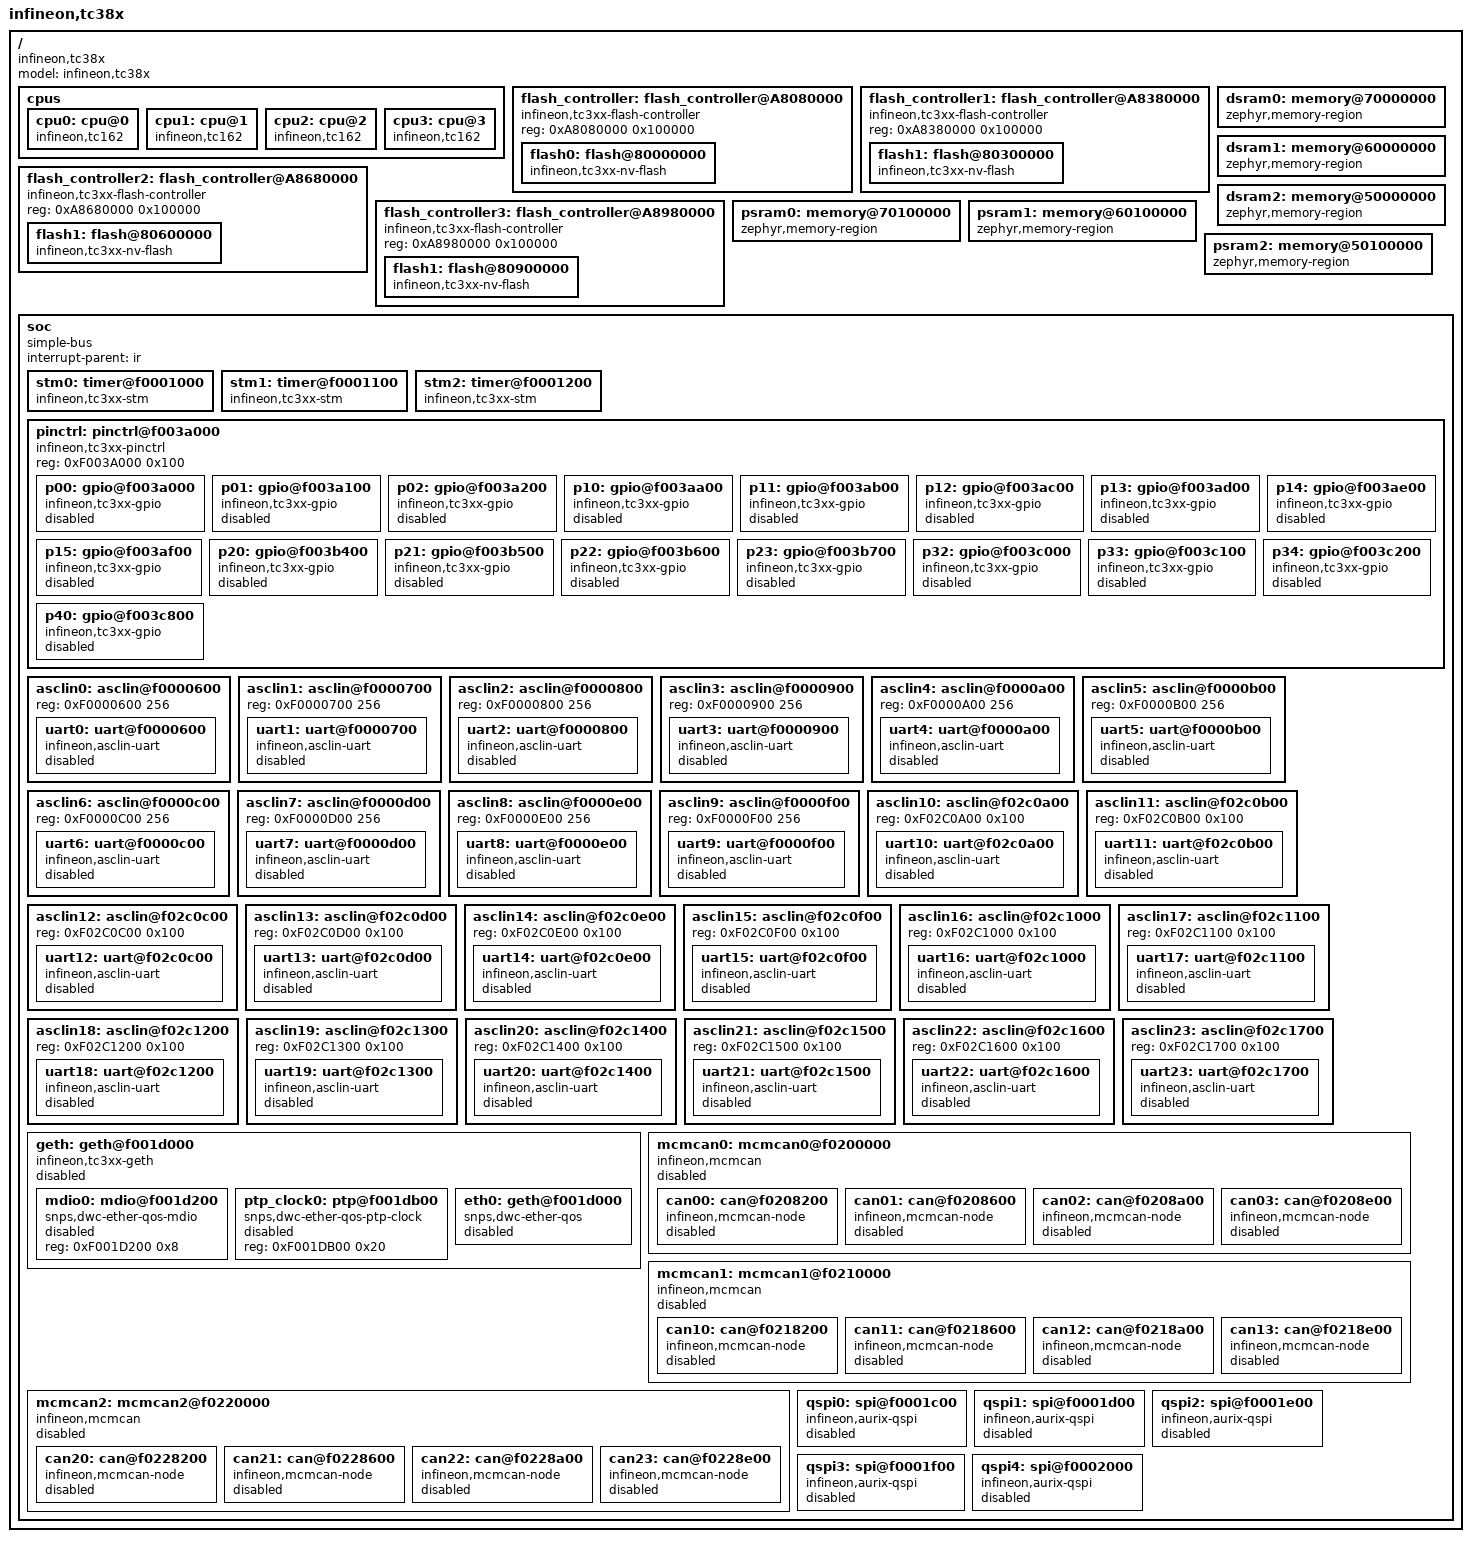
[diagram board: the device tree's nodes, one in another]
/*
 * Copyright (c) 2024 Infineon Technologies AG
 *
 * SPDX-License-Identifier: Apache-2.0
 */

#include <mem.h>
#include <freq.h>
#include <skeleton.dtsi>
#include <zephyr/dt-bindings/clock/tc3xx_clock.h>
#include <zephyr/dt-bindings/gpio/gpio.h>
#include <infineon/tc3xx/tc3xx-common.dtsi>
#include <infineon/tc3xx/tc38x-irq.h>

/ {
	model = "infineon,tc38x";
	compatible = "infineon,tc38x";

	cpus {
		#address-cells = <1>;
		#size-cells = <0>;

		cpu0: cpu@0 {
			compatible = "infineon,tc162";
			reg = <0>;
			clocks = <&fcpu0>;
		};
		cpu1: cpu@1 {
			compatible = "infineon,tc162";
			reg = <1>;
			clocks = <&fcpu1>;
		};
		cpu2: cpu@2 {
			compatible = "infineon,tc162";
			reg = <2>;
			clocks = <&fcpu2>;
		};
		cpu3: cpu@3 {
			compatible = "infineon,tc162";
			reg = <3>;
			clocks = <&fcpu3>;
		};
	};

	flash_controller: flash_controller@A8080000 {
		compatible = "infineon,tc3xx-flash-controller";
		#address-cells = <1>;
		#size-cells = <1>;
		reg = <0xA8080000 0x100000>;
		flash0: flash@80000000 {
			compatible = "infineon,tc3xx-nv-flash","soc-nv-flash";
			write-block-size = <256>;
			reg = <0x80000000 DT_SIZE_M(2)>;
		};
	};
	flash_controller1: flash_controller@A8380000 {
		compatible = "infineon,tc3xx-flash-controller";
		reg = <0xA8380000 0x100000>;
		#address-cells = <1>;
		#size-cells = <1>;
		flash1: flash@80300000 {
			compatible = "infineon,tc3xx-nv-flash","soc-nv-flash";
			write-block-size = <256>;
			reg = <0x80300000 DT_SIZE_M(2)>;
		};
	};
	flash_controller2: flash_controller@A8680000 {
		compatible = "infineon,tc3xx-flash-controller";
		reg = <0xA8680000 0x100000>;
		#address-cells = <1>;
		#size-cells = <1>;
		flash1: flash@80600000 {
			compatible = "infineon,tc3xx-nv-flash","soc-nv-flash";
			write-block-size = <256>;
			reg = <0x80600000 DT_SIZE_M(2)>;
		};
	};
	flash_controller3: flash_controller@A8980000 {
		compatible = "infineon,tc3xx-flash-controller";
		reg = <0xA8980000 0x100000>;
		#address-cells = <1>;
		#size-cells = <1>;
		flash1: flash@80900000 {
			compatible = "infineon,tc3xx-nv-flash","soc-nv-flash";
			write-block-size = <256>;
			reg = <0x80900000 DT_SIZE_M(2)>;
		};
	};

	dsram0: memory@70000000 {
		compatible = "zephyr,memory-region","mmio-sram";
		reg = <0x70000000 DT_SIZE_K(240)>;
		zephyr,memory-region = "DSRAM0";
	};
	dsram1: memory@60000000 {
		compatible = "zephyr,memory-region","mmio-sram";
		reg = <0x60000000 DT_SIZE_K(240)>;
		zephyr,memory-region = "DSRAM1";
	};
	dsram2: memory@50000000 {
		compatible = "zephyr,memory-region","mmio-sram";
		reg = <0x50000000 DT_SIZE_K(96)>;
		zephyr,memory-region = "DSRAM2";
	};
	dsram2: memory@50000000 {
		compatible = "zephyr,memory-region","mmio-sram";
		reg = <0x40000000 DT_SIZE_K(96)>;
		zephyr,memory-region = "DSRAM3";
	};

	psram0: memory@70100000 {
		compatible = "zephyr,memory-region","mmio-sram";
		reg = <0x70100000 DT_SIZE_K(64)>;
		zephyr,memory-region = "PSRAM0";
	};
	psram1: memory@60100000 {
		compatible = "zephyr,memory-region","mmio-sram";
		reg = <0x60100000 DT_SIZE_K(64)>;
		zephyr,memory-region = "PSRAM1";
	};
	psram2: memory@50100000 {
		compatible = "zephyr,memory-region","mmio-sram";
		reg = <0x50100000 DT_SIZE_K(64)>;
		zephyr,memory-region = "PSRAM2";
	};
	psram2: memory@50100000 {
		compatible = "zephyr,memory-region","mmio-sram";
		reg = <0x40100000 DT_SIZE_K(64)>;
		zephyr,memory-region = "PSRAM3";
	};

	soc {
		#address-cells = <1>;
		#size-cells = <1>;
		interrupt-parent = <&ir>;
		compatible = "simple-bus";
		ranges;

		stm0: timer@f0001000 {
			compatible = "infineon,tc3xx-stm";
			reg = <0xF0001000 256>;
			clocks = <&fstm>;
			interrupts = <192 1>;
		};

		stm1: timer@f0001100 {
			compatible = "infineon,tc3xx-stm";
			reg = <0xF0001100 256>;
			clocks = <&fstm>;
			interrupts = <194 1>;
		};

		stm2: timer@f0001200 {
			compatible = "infineon,tc3xx-stm";
			reg = <0xF0001200 256>;
			clocks = <&fstm>;
			interrupts = <196 1>;
		};

		pinctrl: pinctrl@f003a000 {
			compatible = "infineon,tc3xx-pinctrl";
			reg = <0xF003A000 0x100>;
			#address-cells = <1>;
			#size-cells = <1>;

			p00: gpio@f003a000 {
				compatible = "infineon,tc3xx-gpio";
				reg = <0xF003A000 0x100>;
				gpio-controller;
				#gpio-cells = <2>;
				status = "disabled";
			};
			p01: gpio@f003a100 {
				compatible = "infineon,tc3xx-gpio";
				reg = <0xF003A100 0x100>;
				gpio-controller;
				#gpio-cells = <2>;
				status = "disabled";
			};
			p02: gpio@f003a200 {
				compatible = "infineon,tc3xx-gpio";
				reg = <0xF003A200 0x100>;
				gpio-controller;
				#gpio-cells = <2>;
				status = "disabled";
			};
			p10: gpio@f003aa00 {
				compatible = "infineon,tc3xx-gpio";
				reg = <0xF003AA00 0x100>;
				gpio-controller;
				#gpio-cells = <2>;
				status = "disabled";
			};
			p11: gpio@f003ab00 {
				compatible = "infineon,tc3xx-gpio";
				reg = <0xF003AB00 0x100>;
				gpio-controller;
				#gpio-cells = <2>;
				status = "disabled";
			};
			p12: gpio@f003ac00 {
				compatible = "infineon,tc3xx-gpio";
				reg = <0xF003AC00 0x100>;
				gpio-controller;
				#gpio-cells = <2>;
				status = "disabled";
			};
			p13: gpio@f003ad00 {
				compatible = "infineon,tc3xx-gpio";
				reg = <0xF003AD00 0x100>;
				gpio-controller;
				#gpio-cells = <2>;
				status = "disabled";
			};
			p14: gpio@f003ae00 {
				compatible = "infineon,tc3xx-gpio";
				reg = <0xF003AE00 0x100>;
				gpio-controller;
				#gpio-cells = <2>;
				status = "disabled";
			};
			p15: gpio@f003af00 {
				compatible = "infineon,tc3xx-gpio";
				reg = <0xF003AF00 0x100>;
				gpio-controller;
				#gpio-cells = <2>;
				status = "disabled";
			};
			p20: gpio@f003b400 {
				compatible = "infineon,tc3xx-gpio";
				reg = <0xF003B400 0x100>;
				gpio-controller;
				#gpio-cells = <2>;
				status = "disabled";
			};
			p21: gpio@f003b500 {
				compatible = "infineon,tc3xx-gpio";
				reg = <0xF003B500 0x100>;
				gpio-controller;
				#gpio-cells = <2>;
				status = "disabled";
			};
			p22: gpio@f003b600 {
				compatible = "infineon,tc3xx-gpio";
				reg = <0xF003B600 0x100>;
				gpio-controller;
				#gpio-cells = <2>;
				status = "disabled";
			};
			p23: gpio@f003b700 {
				compatible = "infineon,tc3xx-gpio";
				reg = <0xF003B700 0x100>;
				gpio-controller;
				#gpio-cells = <2>;
				status = "disabled";
			};
			p32: gpio@f003c000 {
				compatible = "infineon,tc3xx-gpio";
				reg = <0xF003C000 0x100>;
				gpio-controller;
				#gpio-cells = <2>;
				status = "disabled";
			};
			p33: gpio@f003c100 {
				compatible = "infineon,tc3xx-gpio";
				reg = <0xF003C100 0x100>;
				gpio-controller;
				#gpio-cells = <2>;
				status = "disabled";
			};
			p34: gpio@f003c200 {
				compatible = "infineon,tc3xx-gpio";
				reg = <0xF003C200 0x100>;
				gpio-controller;
				#gpio-cells = <2>;
				status = "disabled";
			};
			p40: gpio@f003c800 {
				compatible = "infineon,tc3xx-gpio";
				reg = <0xF003C800 0x100>;
				gpio-controller;
				#gpio-cells = <2>;
				status = "disabled";
			};
		};

		asclin0: asclin@f0000600 {
			reg = <0xF0000600 256>;
			#address-cells = <1>;
			#size-cells = <1>;

			uart0: uart@f0000600 {
				compatible = "infineon,asclin-uart";
				reg = <0xF0000600 256>;
				interrupts = <IRQ_ASCLIN_ASCLIN0_TX 2>,
				             <IRQ_ASCLIN_ASCLIN0_RX 3>,
				             <IRQ_ASCLIN_ASCLIN0_ERR 4>;
				interrupt-names = "tx", "rx", "err";
				clocks = <&ccu CLOCK_FASCLINF>, <&ccu CLOCK_FASCLINS>;
				clock-names = "fasclinf", "fasclins";
				status = "disabled";
			};
		};
		asclin1: asclin@f0000700 {
			reg = <0xF0000700 256>;
			#address-cells = <1>;
			#size-cells = <1>;

			uart1: uart@f0000700 {
				compatible = "infineon,asclin-uart";
				reg = <0xF0000700 256>;
				interrupts = <IRQ_ASCLIN_ASCLIN1_TX 2>,
				             <IRQ_ASCLIN_ASCLIN1_RX 3>,
				             <IRQ_ASCLIN_ASCLIN1_ERR 4>;
				interrupt-names = "tx", "rx", "err";
				clocks = <&ccu CLOCK_FASCLINF>, <&ccu CLOCK_FASCLINS>;
				clock-names = "fasclinf", "fasclins";
				status = "disabled";
			};
		};
		asclin2: asclin@f0000800 {
			reg = <0xF0000800 256>;
			#address-cells = <1>;
			#size-cells = <1>;

			uart2: uart@f0000800 {
				compatible = "infineon,asclin-uart";
				reg = <0xF0000800 256>;
				interrupts = <IRQ_ASCLIN_ASCLIN2_TX 2>,
				             <IRQ_ASCLIN_ASCLIN2_RX 3>,
				             <IRQ_ASCLIN_ASCLIN2_ERR 4>;
				interrupt-names = "tx", "rx", "err";
				clocks = <&ccu CLOCK_FASCLINF>, <&ccu CLOCK_FASCLINS>;
				clock-names = "fasclinf", "fasclins";
				status = "disabled";
			};
		};
		asclin3: asclin@f0000900 {
			reg = <0xF0000900 256>;
			#address-cells = <1>;
			#size-cells = <1>;

			uart3: uart@f0000900 {
				compatible = "infineon,asclin-uart";
				reg = <0xF0000900 256>;
				interrupts = <IRQ_ASCLIN_ASCLIN3_TX 2>,
				             <IRQ_ASCLIN_ASCLIN3_RX 3>,
				             <IRQ_ASCLIN_ASCLIN3_ERR 4>;
				interrupt-names = "tx", "rx", "err";
				clocks = <&ccu CLOCK_FASCLINF>, <&ccu CLOCK_FASCLINS>;
				clock-names = "fasclinf", "fasclins";
				status = "disabled";
			};
		};
		asclin4: asclin@f0000a00 {
			reg = <0xF0000A00 256>;
			#address-cells = <1>;
			#size-cells = <1>;

			uart4: uart@f0000a00 {
				compatible = "infineon,asclin-uart";
				reg = <0xF0000A00 256>;
				interrupts = <IRQ_ASCLIN_ASCLIN4_TX 2>,
				             <IRQ_ASCLIN_ASCLIN4_RX 3>,
				             <IRQ_ASCLIN_ASCLIN4_ERR 4>;
				interrupt-names = "tx", "rx", "err";
				clocks = <&ccu CLOCK_FASCLINF>, <&ccu CLOCK_FASCLINS>;
				clock-names = "fasclinf", "fasclins";
				status = "disabled";
			};
		};
		asclin5: asclin@f0000b00 {
			reg = <0xF0000B00 256>;
			#address-cells = <1>;
			#size-cells = <1>;

			uart5: uart@f0000b00 {
				compatible = "infineon,asclin-uart";
				reg = <0xF0000B00 256>;
				interrupts = <IRQ_ASCLIN_ASCLIN5_TX 2>,
				             <IRQ_ASCLIN_ASCLIN5_RX 3>,
				             <IRQ_ASCLIN_ASCLIN5_ERR 4>;
				interrupt-names = "tx", "rx", "err";
				clocks = <&ccu CLOCK_FASCLINF>, <&ccu CLOCK_FASCLINS>;
				clock-names = "fasclinf", "fasclins";
				status = "disabled";
			};
		};
		asclin6: asclin@f0000c00 {
			reg = <0xF0000C00 256>;
			#address-cells = <1>;
			#size-cells = <1>;

			uart6: uart@f0000c00 {
				compatible = "infineon,asclin-uart";
				reg = <0xF0000C00 256>;
				interrupts = <IRQ_ASCLIN_ASCLIN6_TX 2>,
				             <IRQ_ASCLIN_ASCLIN6_RX 3>,
				             <IRQ_ASCLIN_ASCLIN6_ERR 4>;
				interrupt-names = "tx", "rx", "err";
				clocks = <&ccu CLOCK_FASCLINF>, <&ccu CLOCK_FASCLINS>;
				clock-names = "fasclinf", "fasclins";
				status = "disabled";
			};
		};
		asclin7: asclin@f0000d00 {
			reg = <0xF0000D00 256>;
			#address-cells = <1>;
			#size-cells = <1>;

			uart7: uart@f0000d00 {
				compatible = "infineon,asclin-uart";
				reg = <0xF0000D00 256>;
				interrupts = <IRQ_ASCLIN_ASCLIN7_TX 2>,
				             <IRQ_ASCLIN_ASCLIN7_RX 3>,
				             <IRQ_ASCLIN_ASCLIN7_ERR 4>;
				interrupt-names = "tx", "rx", "err";
				clocks = <&ccu CLOCK_FASCLINF>, <&ccu CLOCK_FASCLINS>;
				clock-names = "fasclinf", "fasclins";
				status = "disabled";
			};
		};
		asclin8: asclin@f0000e00 {
			reg = <0xF0000E00 256>;
			#address-cells = <1>;
			#size-cells = <1>;

			uart8: uart@f0000e00 {
				compatible = "infineon,asclin-uart";
				reg = <0xF0000E00 256>;
				interrupts = <IRQ_ASCLIN_ASCLIN8_TX 2>,
				             <IRQ_ASCLIN_ASCLIN8_RX 3>,
				             <IRQ_ASCLIN_ASCLIN8_ERR 4>;
				interrupt-names = "tx", "rx", "err";
				clocks = <&ccu CLOCK_FASCLINF>, <&ccu CLOCK_FASCLINS>;
				clock-names = "fasclinf", "fasclins";
				status = "disabled";
			};
		};
		asclin9: asclin@f0000f00 {
			reg = <0xF0000F00 256>;
			#address-cells = <1>;
			#size-cells = <1>;

			uart9: uart@f0000f00 {
				compatible = "infineon,asclin-uart";
				reg = <0xF0000F00 256>;
				interrupts = <47 2>, <48 3>, <49 4>;
				interrupt-names = "tx", "rx", "err";
				clocks = <&ccu CLOCK_FASCLINF>, <&ccu CLOCK_FASCLINS>;
				clock-names = "fasclinf", "fasclins";
				status = "disabled";
			};
		};
		asclin10: asclin@f02c0a00 {
			reg = <0xF02C0A00 0x100>;
			#address-cells = <1>;
			#size-cells = <1>;

			uart10: uart@f02c0a00 {
				compatible = "infineon,asclin-uart";
				reg = <0xF02C0A00 0x100>;
				interrupts = <IRQ_ASCLIN_ASCLIN10_TX 2>,
				             <IRQ_ASCLIN_ASCLIN10_RX 3>,
				             <IRQ_ASCLIN_ASCLIN10_ERR 4>;
				interrupt-names = "tx", "rx", "err";
				clocks = <&ccu CLOCK_FASCLINF>, <&ccu CLOCK_FASCLINS>;
				clock-names = "fasclinf", "fasclins";
				status = "disabled";
			};
		};
		asclin11: asclin@f02c0b00 {
			reg = <0xF02C0B00 0x100>;
			#address-cells = <1>;
			#size-cells = <1>;

			uart11: uart@f02c0b00 {
				compatible = "infineon,asclin-uart";
				reg = <0xF02C0B00 0x100>;
				interrupts = <IRQ_ASCLIN_ASCLIN11_TX 2>,
				             <IRQ_ASCLIN_ASCLIN11_RX 3>,
				             <IRQ_ASCLIN_ASCLIN11_ERR 4>;
				interrupt-names = "tx", "rx", "err";
				clocks = <&ccu CLOCK_FASCLINF>, <&ccu CLOCK_FASCLINS>;
				clock-names = "fasclinf", "fasclins";
				status = "disabled";
			};
		};
		asclin12: asclin@f02c0c00 {
			reg = <0xF02C0C00 0x100>;
			#address-cells = <1>;
			#size-cells = <1>;

			uart12: uart@f02c0c00 {
				compatible = "infineon,asclin-uart";
				reg = <0xF02C0C00 0x100>;
				interrupts = <IRQ_ASCLIN_ASCLIN12_TX 2>,
				             <IRQ_ASCLIN_ASCLIN12_RX 3>,
				             <IRQ_ASCLIN_ASCLIN12_ERR 4>;
				interrupt-names = "tx", "rx", "err";
				clocks = <&ccu CLOCK_FASCLINF>, <&ccu CLOCK_FASCLINS>;
				clock-names = "fasclinf", "fasclins";
				status = "disabled";
			};
		};
		asclin13: asclin@f02c0d00 {
			reg = <0xF02C0D00 0x100>;
			#address-cells = <1>;
			#size-cells = <1>;

			uart13: uart@f02c0d00 {
				compatible = "infineon,asclin-uart";
				reg = <0xF02C0D00 0x100>;
				interrupts = <IRQ_ASCLIN_ASCLIN13_TX 2>,
				             <IRQ_ASCLIN_ASCLIN13_RX 3>,
				             <IRQ_ASCLIN_ASCLIN13_ERR 4>;
				interrupt-names = "tx", "rx", "err";
				clocks = <&ccu CLOCK_FASCLINF>, <&ccu CLOCK_FASCLINS>;
				clock-names = "fasclinf", "fasclins";
				status = "disabled";
			};
		};
		asclin14: asclin@f02c0e00 {
			reg = <0xF02C0E00 0x100>;
			#address-cells = <1>;
			#size-cells = <1>;

			uart14: uart@f02c0e00 {
				compatible = "infineon,asclin-uart";
				reg = <0xF02C0E00 0x100>;
				interrupts = <IRQ_ASCLIN_ASCLIN14_TX 2>,
				             <IRQ_ASCLIN_ASCLIN14_RX 3>,
				             <IRQ_ASCLIN_ASCLIN14_ERR 4>;
				interrupt-names = "tx", "rx", "err";
				clocks = <&ccu CLOCK_FASCLINF>, <&ccu CLOCK_FASCLINS>;
				clock-names = "fasclinf", "fasclins";
				status = "disabled";
			};
		};
		asclin15: asclin@f02c0f00 {
			reg = <0xF02C0F00 0x100>;
			#address-cells = <1>;
			#size-cells = <1>;

			uart15: uart@f02c0f00 {
				compatible = "infineon,asclin-uart";
				reg = <0xF02C0F00 0x100>;
				interrupts = <IRQ_ASCLIN_ASCLIN15_TX 2>,
				             <IRQ_ASCLIN_ASCLIN15_RX 3>,
				             <IRQ_ASCLIN_ASCLIN15_ERR 4>;
				interrupt-names = "tx", "rx", "err";
				clocks = <&ccu CLOCK_FASCLINF>, <&ccu CLOCK_FASCLINS>;
				clock-names = "fasclinf", "fasclins";
				status = "disabled";
			};
		};
		asclin16: asclin@f02c1000 {
			reg = <0xF02C1000 0x100>;
			#address-cells = <1>;
			#size-cells = <1>;

			uart16: uart@f02c1000 {
				compatible = "infineon,asclin-uart";
				reg = <0xF02C1000 0x100>;
				interrupts = <IRQ_ASCLIN_ASCLIN16_TX 2>,
				             <IRQ_ASCLIN_ASCLIN16_RX 3>,
				             <IRQ_ASCLIN_ASCLIN16_ERR 4>;
				interrupt-names = "tx", "rx", "err";
				clocks = <&ccu CLOCK_FASCLINF>, <&ccu CLOCK_FASCLINS>;
				clock-names = "fasclinf", "fasclins";
				status = "disabled";
			};
		};
		asclin17: asclin@f02c1100 {
			reg = <0xF02C1100 0x100>;
			#address-cells = <1>;
			#size-cells = <1>;

			uart17: uart@f02c1100 {
				compatible = "infineon,asclin-uart";
				reg = <0xF02C1100 0x100>;
				interrupts = <IRQ_ASCLIN_ASCLIN17_TX 2>,
				             <IRQ_ASCLIN_ASCLIN17_RX 3>,
				             <IRQ_ASCLIN_ASCLIN17_ERR 4>;
				interrupt-names = "tx", "rx", "err";
				clocks = <&ccu CLOCK_FASCLINF>, <&ccu CLOCK_FASCLINS>;
				clock-names = "fasclinf", "fasclins";
				status = "disabled";
			};
		};
		asclin18: asclin@f02c1200 {
			reg = <0xF02C1200 0x100>;
			#address-cells = <1>;
			#size-cells = <1>;

			uart18: uart@f02c1200 {
				compatible = "infineon,asclin-uart";
				reg = <0xF02C1200 0x100>;
				interrupts = <IRQ_ASCLIN_ASCLIN18_TX 2>,
				             <IRQ_ASCLIN_ASCLIN18_RX 3>,
				             <IRQ_ASCLIN_ASCLIN18_ERR 4>;
				interrupt-names = "tx", "rx", "err";
				clocks = <&ccu CLOCK_FASCLINF>, <&ccu CLOCK_FASCLINS>;
				clock-names = "fasclinf", "fasclins";
				status = "disabled";
			};
		};
		asclin19: asclin@f02c1300 {
			reg = <0xF02C1300 0x100>;
			#address-cells = <1>;
			#size-cells = <1>;

			uart19: uart@f02c1300 {
				compatible = "infineon,asclin-uart";
				reg = <0xF02C1300 0x100>;
				interrupts = <IRQ_ASCLIN_ASCLIN19_TX 2>,
				             <IRQ_ASCLIN_ASCLIN19_RX 3>,
				             <IRQ_ASCLIN_ASCLIN19_ERR 4>;
				interrupt-names = "tx", "rx", "err";
				clocks = <&ccu CLOCK_FASCLINF>, <&ccu CLOCK_FASCLINS>;
				clock-names = "fasclinf", "fasclins";
				status = "disabled";
			};
		};
		asclin20: asclin@f02c1400 {
			reg = <0xF02C1400 0x100>;
			#address-cells = <1>;
			#size-cells = <1>;

			uart20: uart@f02c1400 {
				compatible = "infineon,asclin-uart";
				reg = <0xF02C1400 0x100>;
				interrupts = <IRQ_ASCLIN_ASCLIN20_TX 2>,
				             <IRQ_ASCLIN_ASCLIN20_RX 3>,
				             <IRQ_ASCLIN_ASCLIN20_ERR 4>;
				interrupt-names = "tx", "rx", "err";
				clocks = <&ccu CLOCK_FASCLINF>, <&ccu CLOCK_FASCLINS>;
				clock-names = "fasclinf", "fasclins";
				status = "disabled";
			};
		};
		asclin21: asclin@f02c1500 {
			reg = <0xF02C1500 0x100>;
			#address-cells = <1>;
			#size-cells = <1>;

			uart21: uart@f02c1500 {
				compatible = "infineon,asclin-uart";
				reg = <0xF02C1500 0x100>;
				interrupts = <IRQ_ASCLIN_ASCLIN21_TX 2>,
				             <IRQ_ASCLIN_ASCLIN21_RX 3>,
				             <IRQ_ASCLIN_ASCLIN21_ERR 4>;
				interrupt-names = "tx", "rx", "err";
				clocks = <&ccu CLOCK_FASCLINF>, <&ccu CLOCK_FASCLINS>;
				clock-names = "fasclinf", "fasclins";
				status = "disabled";
			};
		};
		asclin22: asclin@f02c1600 {
			reg = <0xF02C1600 0x100>;
			#address-cells = <1>;
			#size-cells = <1>;

			uart22: uart@f02c1600 {
				compatible = "infineon,asclin-uart";
				reg = <0xF02C1600 0x100>;
				interrupts = <IRQ_ASCLIN_ASCLIN22_TX 2>,
				             <IRQ_ASCLIN_ASCLIN22_RX 3>,
				             <IRQ_ASCLIN_ASCLIN22_ERR 4>;
				interrupt-names = "tx", "rx", "err";
				clocks = <&ccu CLOCK_FASCLINF>, <&ccu CLOCK_FASCLINS>;
				clock-names = "fasclinf", "fasclins";
				status = "disabled";
			};
		};
		asclin23: asclin@f02c1700 {
			reg = <0xF02C1700 0x100>;
			#address-cells = <1>;
			#size-cells = <1>;

			uart23: uart@f02c1700 {
				compatible = "infineon,asclin-uart";
				reg = <0xF02C1700 0x100>;
				interrupts = <IRQ_ASCLIN_ASCLIN23_TX 2>,
				             <IRQ_ASCLIN_ASCLIN23_RX 3>,
				             <IRQ_ASCLIN_ASCLIN23_ERR 4>;
				interrupt-names = "tx", "rx", "err";
				clocks = <&ccu CLOCK_FASCLINF>, <&ccu CLOCK_FASCLINS>;
				clock-names = "fasclinf", "fasclins";
				status = "disabled";
			};
		};

		geth: geth@f001d000 {
			reg = <0xF001D000 0x2100>;
			compatible = "infineon,tc3xx-geth";
			#address-cells = <1>;
			#size-cells = <1>;
			clocks = <&ccu CLOCK_FSPB>, <&ccu CLOCK_FGETH>, <&ccu CLOCK_FGETH>;
			clock-names = "csr", "app", "ptp";
			status = "disabled";

			mdio0: mdio@f001d200 {
				compatible = "snps,dwc-ether-qos-mdio";
				reg = <0xF001D200 0x8>;
				#address-cells = <1>;
				#size-cells = <0>;
				status = "disabled";
			};

			ptp_clock0: ptp@f001db00 {
				compatible = "snps,dwc-ether-qos-ptp-clock";
				reg = <0xF001DB00 0x20>;
				status = "disabled";
			};

			eth0: geth@f001d000 {
				compatible = "snps,dwc-ether-qos";
				reg = <0xF001D000 0x2000>;
				interrupts = <IRQ_GETH_GETH0_SR0 10>,
				             <IRQ_GETH_GETH0_SR2 12>,
				             <IRQ_GETH_GETH0_SR3 13>,
				             <IRQ_GETH_GETH0_SR4 14>,
				             <IRQ_GETH_GETH0_SR5 15>,
				             <IRQ_GETH_GETH0_SR6 16>,
				             <IRQ_GETH_GETH0_SR7 17>,
				             <IRQ_GETH_GETH0_SR8 18>,
				             <IRQ_GETH_GETH0_SR9 19>;
				interrupt-names = "common",
				                  "tx0",
				                  "tx1",
				                  "tx2",
				                  "tx3",
				                  "rx0",
				                  "rx1",
				                  "rx2",
				                  "rx3";
				ptp-clock = <&ptp_clock0>;
				snps,address-aligned-burst;
				snps,fixed-burst-length;
				snps,burst-length = <8>;
				status = "disabled";
			};
		};

		mcmcan0: mcmcan0@f0200000 {
			compatible = "infineon,mcmcan";
			#address-cells = <1>;
			#size-cells = <1>;
			reg = <0xF0200000 0x9000>;
			clocks = <&ccu CLOCK_FMCAN>, <&ccu CLOCK_FMCANH>;
			status = "disabled";

			can00: can@f0208200 {
				compatible = "infineon,mcmcan-node";
				reg = <0xF0208200 0x200>, <0xF0200000 0x8000>;
				reg-names = "m_can", "message_ram";
				interrupts = <IRQ_CAN_CAN0_INT0 10>, <IRQ_CAN_CAN0_INT1 11>;
				interrupt-names = "line0", "line1";
				bosch,mram-cfg = <0x0 32 32 32 32 0 16 16>;
				sample-point = <875>;
				sample-point-data = <875>;
				bitrate = <500000>;
				bitrate-data = <2000000>;
				status = "disabled";
			};
			can01: can@f0208600 {
				compatible = "infineon,mcmcan-node";
				reg = <0xF0208600 0x200>, <0xF0200000 0x8000>;
				reg-names = "m_can", "message_ram";
				interrupts = <IRQ_CAN_CAN0_INT2 10>, <IRQ_CAN_CAN0_INT3 11>;
				interrupt-names = "line0", "line1";
				bosch,mram-cfg = <0x0 32 32 32 32 0 16 16>;
				sample-point = <875>;
				sample-point-data = <875>;
				bitrate = <500000>;
				bitrate-data = <2000000>;
				status = "disabled";
			};
			can02: can@f0208a00 {
				compatible = "infineon,mcmcan-node";
				reg = <0xF0208A00 0x200>, <0xF0200000 0x8000>;
				reg-names = "m_can", "message_ram";
				interrupts = <IRQ_CAN_CAN0_INT4 10>, <IRQ_CAN_CAN0_INT5 11>;
				interrupt-names = "line0", "line1";
				bosch,mram-cfg = <0x0 32 32 32 32 0 16 16>;
				sample-point = <875>;
				sample-point-data = <875>;
				bitrate = <500000>;
				bitrate-data = <2000000>;
				status = "disabled";
			};
			can03: can@f0208e00 {
				compatible = "infineon,mcmcan-node";
				reg = <0xF0208E00 0x200>, <0xF0200000 0x8000>;
				reg-names = "m_can", "message_ram";
				interrupts = <IRQ_CAN_CAN0_INT6 10>, <IRQ_CAN_CAN0_INT7 11>;
				interrupt-names = "line0", "line1";
				bosch,mram-cfg = <0x0 32 32 32 32 0 16 16>;
				sample-point = <875>;
				sample-point-data = <875>;
				bitrate = <500000>;
				bitrate-data = <2000000>;
				status = "disabled";
			};
		};

		mcmcan1: mcmcan1@f0210000 {
			compatible = "infineon,mcmcan";
			#address-cells = <1>;
			#size-cells = <1>;
			reg = <0xF0210000 0x9000>;
			clocks = <&ccu CLOCK_FMCAN>, <&ccu CLOCK_FMCANH>;
			status = "disabled";

			can10: can@f0218200 {
				compatible = "infineon,mcmcan-node";
				reg = <0xF0218200 0x200>, <0xF0210000 0x8000>;
				reg-names = "m_can", "message_ram";
				interrupts = <IRQ_CAN_CAN1_INT0 10>, <IRQ_CAN_CAN1_INT1 11>;
				interrupt-names = "line0", "line1";
				bosch,mram-cfg = <0x0 32 32 32 32 0 16 16>;
				sample-point = <875>;
				sample-point-data = <875>;
				bitrate = <500000>;
				bitrate-data = <2000000>;
				status = "disabled";
			};
			can11: can@f0218600 {
				compatible = "infineon,mcmcan-node";
				reg = <0xF0218600 0x200>, <0xF0210000 0x8000>;
				reg-names = "m_can", "message_ram";
				interrupts = <IRQ_CAN_CAN1_INT2 10>, <IRQ_CAN_CAN1_INT3 11>;
				interrupt-names = "line0", "line1";
				bosch,mram-cfg = <0x0 32 32 32 32 0 16 16>;
				sample-point = <875>;
				sample-point-data = <875>;
				bitrate = <500000>;
				bitrate-data = <2000000>;
				status = "disabled";
			};
			can12: can@f0218a00 {
				compatible = "infineon,mcmcan-node";
				reg = <0xF0218A00 0x200>, <0xF0210000 0x8000>;
				reg-names = "m_can", "message_ram";
				interrupts = <IRQ_CAN_CAN1_INT4 10>, <IRQ_CAN_CAN1_INT5 11>;
				interrupt-names = "line0", "line1";
				bosch,mram-cfg = <0x0 32 32 32 32 0 16 16>;
				sample-point = <875>;
				sample-point-data = <875>;
				bitrate = <500000>;
				bitrate-data = <2000000>;
				status = "disabled";
			};
			can13: can@f0218e00 {
				compatible = "infineon,mcmcan-node";
				reg = <0xF0218E00 0x200>, <0xF0210000 0x8000>;
				reg-names = "m_can", "message_ram";
				interrupts = <IRQ_CAN_CAN1_INT6 10>, <IRQ_CAN_CAN1_INT7 11>;
				interrupt-names = "line0", "line1";
				bosch,mram-cfg = <0x0 32 32 32 32 0 16 16>;
				sample-point = <875>;
				sample-point-data = <875>;
				bitrate = <500000>;
				bitrate-data = <2000000>;
				status = "disabled";
			};
		};
		mcmcan2: mcmcan2@f0220000 {
			compatible = "infineon,mcmcan";
			#address-cells = <1>;
			#size-cells = <1>;
			reg = <0xF0220000 0x9000>;
			clocks = <&ccu CLOCK_FMCAN>, <&ccu CLOCK_FMCANH>;
			status = "disabled";

			can20: can@f0228200 {
				compatible = "infineon,mcmcan-node";
				reg = <0xF0228200 0x200>, <0xF0220000 0x8000>;
				reg-names = "m_can", "message_ram";
				interrupts = <IRQ_CAN_CAN2_INT0 10>, <IRQ_CAN_CAN2_INT1 11>;
				interrupt-names = "line0", "line1";
				bosch,mram-cfg = <0x0 32 32 32 32 0 16 16>;
				sample-point = <875>;
				sample-point-data = <875>;
				bitrate = <500000>;
				bitrate-data = <2000000>;
				status = "disabled";
			};
			can21: can@f0228600 {
				compatible = "infineon,mcmcan-node";
				reg = <0xF0228600 0x200>, <0xF0220000 0x8000>;
				reg-names = "m_can", "message_ram";
				interrupts = <IRQ_CAN_CAN2_INT2 10>, <IRQ_CAN_CAN2_INT3 11>;
				interrupt-names = "line0", "line1";
				bosch,mram-cfg = <0x0 32 32 32 32 0 16 16>;
				sample-point = <875>;
				sample-point-data = <875>;
				bitrate = <500000>;
				bitrate-data = <2000000>;
				status = "disabled";
			};
			can22: can@f0228a00 {
				compatible = "infineon,mcmcan-node";
				reg = <0xF0228A00 0x200>, <0xF0220000 0x8000>;
				reg-names = "m_can", "message_ram";
				interrupts = <IRQ_CAN_CAN2_INT4 10>, <IRQ_CAN_CAN2_INT5 11>;
				interrupt-names = "line0", "line1";
				bosch,mram-cfg = <0x0 32 32 32 32 0 16 16>;
				sample-point = <875>;
				sample-point-data = <875>;
				bitrate = <500000>;
				bitrate-data = <2000000>;
				status = "disabled";
			};
			can23: can@f0228e00 {
				compatible = "infineon,mcmcan-node";
				reg = <0xF0228E00 0x200>, <0xF0220000 0x8000>;
				reg-names = "m_can", "message_ram";
				interrupts = <IRQ_CAN_CAN2_INT6 10>, <IRQ_CAN_CAN2_INT7 11>;
				interrupt-names = "line0", "line1";
				bosch,mram-cfg = <0x0 32 32 32 32 0 16 16>;
				sample-point = <875>;
				sample-point-data = <875>;
				bitrate = <500000>;
				bitrate-data = <2000000>;
				status = "disabled";
			};
		};

		qspi0: spi@f0001c00 {
			compatible = "infineon,aurix-qspi";
			reg = <0xF0001C00 0x100>;
			#address-cells = <1>;
			#size-cells = <0>;
			interrupts = <IRQ_QSPI_QSPI0_TX 0x2>,
			             <IRQ_QSPI_QSPI0_RX 0x3>,
			             <IRQ_QSPI_QSPI0_ERR 0x3>;
			interrupt-names = "tx", "rx", "err";
			clocks = <&ccu CLOCK_FQSPI>;
			status = "disabled";
		};
		qspi1: spi@f0001d00 {
			compatible = "infineon,aurix-qspi";
			reg = <0xF0001d00 0x100>;
			#address-cells = <1>;
			#size-cells = <0>;
			interrupts = <IRQ_QSPI_QSPI1_TX 0x2>,
			             <IRQ_QSPI_QSPI1_RX 0x3>,
			             <IRQ_QSPI_QSPI1_ERR 0x3>;
			interrupt-names = "tx", "rx", "err";
			clocks = <&ccu CLOCK_FQSPI>;
			status = "disabled";
		};
		qspi2: spi@f0001e00 {
			compatible = "infineon,aurix-qspi";
			reg = <0xF0001E00 0x100>;
			#address-cells = <1>;
			#size-cells = <0>;
			interrupts = <IRQ_QSPI_QSPI2_TX 0x2>,
			             <IRQ_QSPI_QSPI2_RX 0x3>,
			             <IRQ_QSPI_QSPI2_ERR 0x3>;
			interrupt-names = "tx", "rx", "err";
			clocks = <&ccu CLOCK_FQSPI>;
			status = "disabled";
		};
		qspi3: spi@f0001f00 {
			compatible = "infineon,aurix-qspi";
			reg = <0xF0001f00 0x100>;
			#address-cells = <1>;
			#size-cells = <0>;
			interrupts = <IRQ_QSPI_QSPI3_TX 0x2>,
			             <IRQ_QSPI_QSPI3_RX 0x3>,
			             <IRQ_QSPI_QSPI3_ERR 0x3>;
			interrupt-names = "tx", "rx", "err";
			clocks = <&ccu CLOCK_FQSPI>;
			status = "disabled";
		};
		qspi4: spi@f0002000 {
			compatible = "infineon,aurix-qspi";
			reg = <0xF0002000 0x100>;
			#address-cells = <1>;
			#size-cells = <0>;
			interrupts = <IRQ_QSPI_QSPI4_TX 0x2>,
			             <IRQ_QSPI_QSPI4_RX 0x3>,
			             <IRQ_QSPI_QSPI4_ERR 0x3>;
			interrupt-names = "tx", "rx", "err";
			clocks = <&ccu CLOCK_FQSPI>;
			status = "disabled";
		};
	};
};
